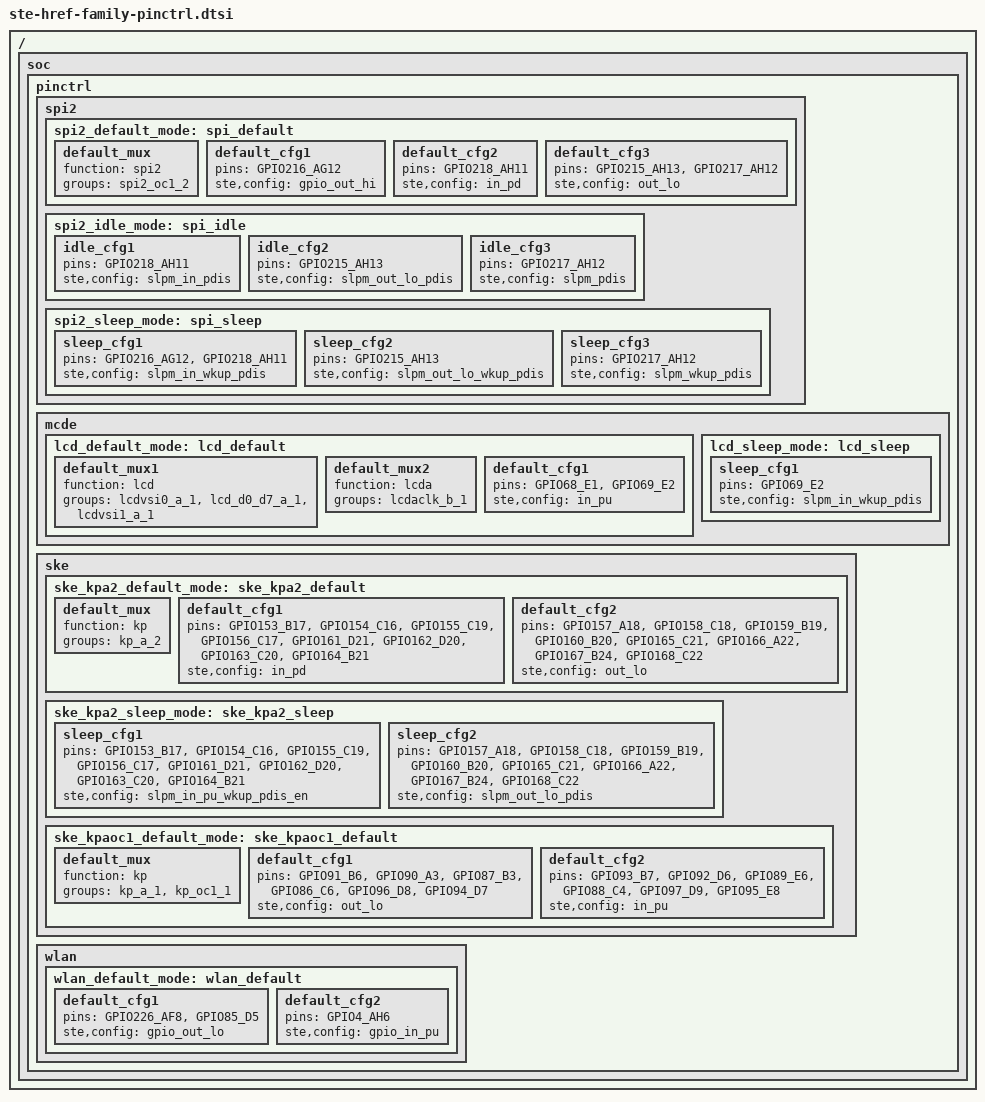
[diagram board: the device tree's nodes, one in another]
#include "ste-dbx5x0-pinctrl.dtsi"
/ {
	soc {
		pinctrl {
			spi2 {
				spi2_default_mode: spi_default {
					default_mux {
						function = "spi2";
						groups = "spi2_oc1_2";
					};
					default_cfg1 {
						pins = "GPIO216_AG12";  
						ste,config = <&gpio_out_hi>;
					};
					default_cfg2 {
						pins = "GPIO218_AH11";  
						ste,config = <&in_pd>;
					};
					default_cfg3 {
						pins =
						"GPIO215_AH13",  
						"GPIO217_AH12";  
						ste,config = <&out_lo>;
					};
				};
				spi2_idle_mode: spi_idle {
					idle_cfg1 {
						pins = "GPIO218_AH11";  
						ste,config = <&slpm_in_pdis>;
					};
					idle_cfg2 {
						pins = "GPIO215_AH13";  
						ste,config = <&slpm_out_lo_pdis>;
					};
					idle_cfg3 {
						pins = "GPIO217_AH12";  
						ste,config = <&slpm_pdis>;
					};
				};
				spi2_sleep_mode: spi_sleep {
					sleep_cfg1 {
						pins =
						"GPIO216_AG12",  
						"GPIO218_AH11";  
						ste,config = <&slpm_in_wkup_pdis>;
					};
					sleep_cfg2 {
						pins = "GPIO215_AH13";  
						ste,config = <&slpm_out_lo_wkup_pdis>;
					};
					sleep_cfg3 {
						pins = "GPIO217_AH12";  
						ste,config = <&slpm_wkup_pdis>;
					};
				};
			};
			mcde {
				lcd_default_mode: lcd_default {
					default_mux1 {
						function = "lcd";
						groups =
						"lcdvsi0_a_1",  
						"lcd_d0_d7_a_1",  
						"lcdvsi1_a_1";  
					};
					default_mux2 {
						function = "lcda";
						groups =
						"lcdaclk_b_1";  
					};
					default_cfg1 {
						pins =
						"GPIO68_E1",  
						"GPIO69_E2";  
						ste,config = <&in_pu>;
					};
				};
				lcd_sleep_mode: lcd_sleep {
					sleep_cfg1 {
						pins = "GPIO69_E2";  
						ste,config = <&slpm_in_wkup_pdis>;
					};
				};
			};
			ske {
				ske_kpa2_default_mode: ske_kpa2_default {
					default_mux {
						function = "kp";
						groups = "kp_a_2";
					};
					default_cfg1 {
						pins =
						"GPIO153_B17",  
						"GPIO154_C16",  
						"GPIO155_C19",  
						"GPIO156_C17",  
						"GPIO161_D21",  
						"GPIO162_D20",  
						"GPIO163_C20",  
						"GPIO164_B21";  
						ste,config = <&in_pd>;
					};
					default_cfg2 {
						pins =
						"GPIO157_A18",  
						"GPIO158_C18",  
						"GPIO159_B19",  
						"GPIO160_B20",  
						"GPIO165_C21",  
						"GPIO166_A22",  
						"GPIO167_B24",  
						"GPIO168_C22";  
						ste,config = <&out_lo>;
					};
				};
				ske_kpa2_sleep_mode: ske_kpa2_sleep {
					sleep_cfg1 {
						pins =
						"GPIO153_B17",  
						"GPIO154_C16",  
						"GPIO155_C19",  
						"GPIO156_C17",  
						"GPIO161_D21",  
						"GPIO162_D20",  
						"GPIO163_C20",  
						"GPIO164_B21";  
						ste,config = <&slpm_in_pu_wkup_pdis_en>;
					};
					sleep_cfg2 {
						pins =
						"GPIO157_A18",  
						"GPIO158_C18",  
						"GPIO159_B19",  
						"GPIO160_B20",  
						"GPIO165_C21",  
						"GPIO166_A22",  
						"GPIO167_B24",  
						"GPIO168_C22";  
						ste,config = <&slpm_out_lo_pdis>;
					};
				};
				ske_kpaoc1_default_mode: ske_kpaoc1_default {
					default_mux {
						function = "kp";
						groups = "kp_a_1", "kp_oc1_1";
					};
					default_cfg1 {
						pins =
						"GPIO91_B6",  
						"GPIO90_A3",  
						"GPIO87_B3",  
						"GPIO86_C6",  
						"GPIO96_D8",  
						"GPIO94_D7";  
						ste,config = <&out_lo>;
					};
					default_cfg2 {
						pins =
						"GPIO93_B7",  
						"GPIO92_D6",  
						"GPIO89_E6",  
						"GPIO88_C4",  
						"GPIO97_D9",  
						"GPIO95_E8";  
						ste,config = <&in_pu>;
					};
				};
			};
			wlan {
				wlan_default_mode: wlan_default {
					default_cfg1 {
						pins =
						"GPIO226_AF8",  
						"GPIO85_D5";  
						ste,config = <&gpio_out_lo>;
					};
					default_cfg2 {
						pins = "GPIO4_AH6";  
						ste,config = <&gpio_in_pu>;
					};
				};
			};
		};
	};
};
